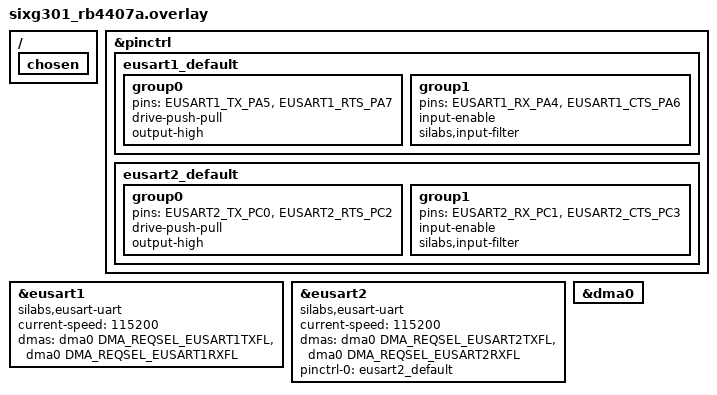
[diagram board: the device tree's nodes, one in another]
/*
 * Copyright (c) 2026 Silicon Laboratories Inc.
 *
 * SPDX-License-Identifier: Apache-2.0
 */

/ {
	chosen {
		/delete-property/ zephyr,display;
	};
};

/delete-node/ &ls013b7dh03;

/*
 * Connect EXP[4,6,8,10] with EXP[7,9,11,13] on the Expension Pin header
 */

&pinctrl {
	eusart1_default: eusart1_default {
		group0 {
			pins = <EUSART1_TX_PA5>, <EUSART1_RTS_PA7>;
			drive-push-pull;
			output-high;
		};

		group1 {
			pins = <EUSART1_RX_PA4>, <EUSART1_CTS_PA6>;
			input-enable;
			silabs,input-filter;
		};
	};

	eusart2_default: eusart2_default {
		group0 {
			pins = <EUSART2_TX_PC0>, <EUSART2_RTS_PC2>;
			drive-push-pull;
			output-high;
		};

		group1 {
			pins = <EUSART2_RX_PC1>, <EUSART2_CTS_PC3>;
			input-enable;
			silabs,input-filter;
		};
	};
};

dut: &eusart1 {
	compatible = "silabs,eusart-uart";
	current-speed = <115200>;
	dmas = <&dma0 DMA_REQSEL_EUSART1TXFL>,
	       <&dma0 DMA_REQSEL_EUSART1RXFL>;
	dma-names = "tx", "rx";
	status = "okay";

	/delete-property/ cs-gpios;
};

dut_aux: &eusart2 {
	compatible = "silabs,eusart-uart";
	current-speed = <115200>;
	dmas = <&dma0 DMA_REQSEL_EUSART2TXFL>,
	       <&dma0 DMA_REQSEL_EUSART2RXFL>;
	dma-names = "tx", "rx";
	pinctrl-0 = <&eusart2_default>;
	pinctrl-names = "default";
	status = "okay";
};

&dma0 {
	status = "okay";
};
